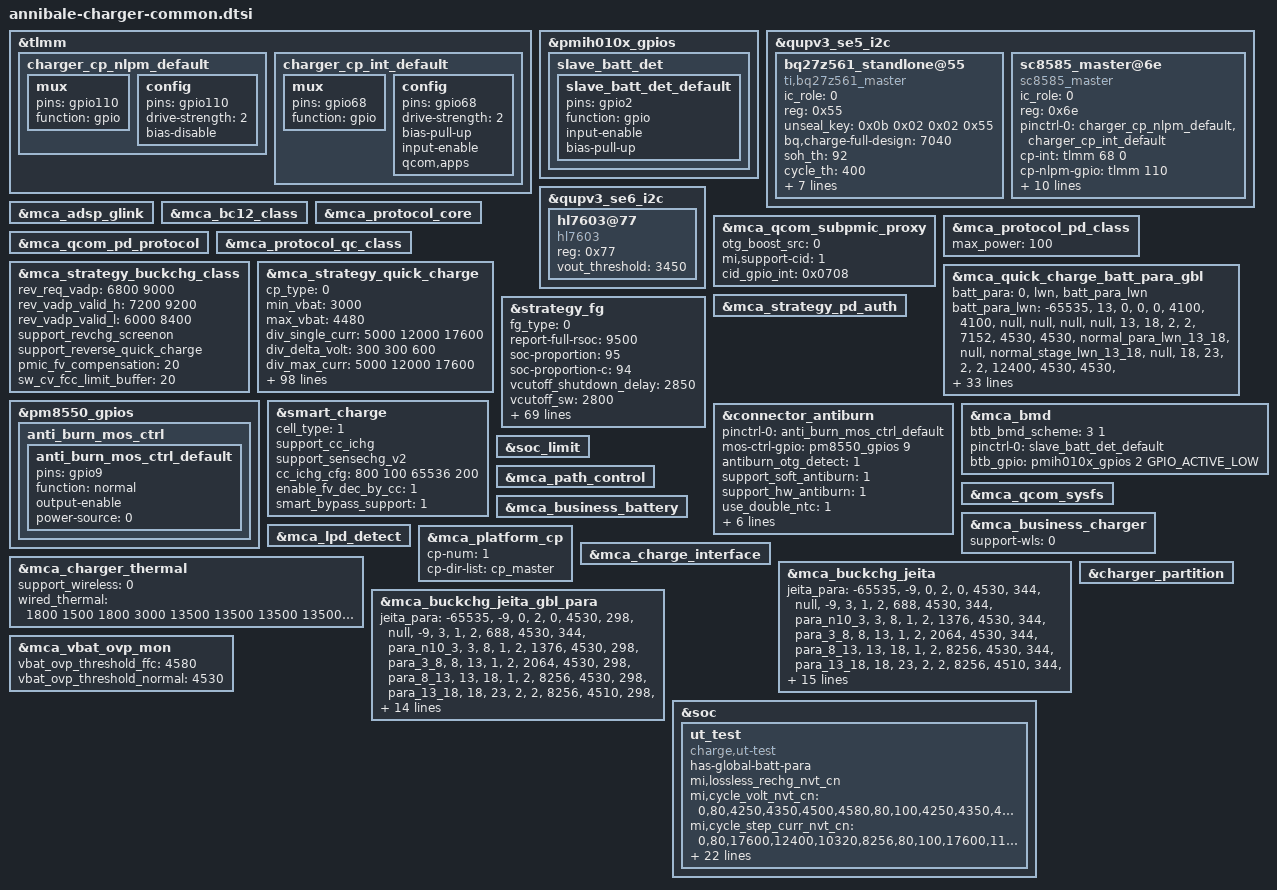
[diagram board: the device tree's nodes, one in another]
#include "mca.dtsi"

&tlmm {
	charger_cp_nlpm_default: charger_cp_nlpm_default {
		mux {
			pins = "gpio110";
			function = "gpio";
		};
		config {
			pins = "gpio110";
			drive-strength = <2>;   /* 2 mA */
			bias-disable;
		};
	};
	charger_cp_int_default: charger_cp_int_default {
		mux {
			pins = "gpio68";
			function = "gpio";
		};
		config {
			pins = "gpio68";
			drive-strength = <2>;   /* 2 mA */
			bias-pull-up;
			input-enable;
			qcom,apps;
		};
	};
};

&pmih010x_gpios {
	slave_batt_det {
		slave_batt_det_default: slave_batt_det_default {
			pins = "gpio2";
			function = "gpio";
			input-enable;
			bias-pull-up;
		};
	};
};


&qupv3_se5_i2c {
	status = "ok";
	#address-cells = <1>;
	#size-cells = <0>;
	bq27z561_standlone@55 {
		compatible = "ti,bq27z561_master";
		ic_role = <0>;
		reg = <0x55>;
		unseal_key = /bits/ 8 <0x0b 0x02 0x02 0x55>;
		bq,charge-full-design = <7040>;
		soh_th = <92>;
		cycle_th = <400>;
		cycle_step = <50>;
		resistance-id = <100000>;
		support-voltage-record-level;
		version_number = /bits/ 8 <0x43>;
		start_byte_address = /bits/ 8 <10>;
		byte_length = /bits/ 8 <6>;
		record_voltage = /bits/ 8 <0xb2 0x0c 0x66 0x0d 0x88 0x13>;
		status = "ok";
	};

	sc8585_master@6e {
		compatible = "sc8585_master";
		status = "ok";
		ic_role = <0>;
		reg = <0x6e>;
		pinctrl-names = "default";
		pinctrl-0 = <&charger_cp_nlpm_default>,<&charger_cp_int_default>;
		cp-int= <&tlmm 68 0>;
		cp-nlpm-gpio = <&tlmm 110 0x00>;
		bat-ovp-threshold = <4750>;
		bat-ovp-alarm-threshold = <4650>;
		bus-ovp-threshold = <21000 11000 6000>;
		usb-ovp-threshold = <21000 14000 6500>;
		bus-ocp-threshold = <5100 5850 5000>;
		wpc-ovp-threshold = <21000>;
		out-ovp-threshold = <5000>;
		pmid2-uvp-threshold = <100>;
		pmid2-ovp-threshold = <600>;
		support_reverse_quick_charge;
	};
};

&qupv3_se6_i2c {
	status = "ok";
	#address-cells = <1>;
	#size-cells = <0>;
	hl7603@77 {
		compatible = "hl7603";
		reg = <0x77>;
		vout_threshold = <3450>;
	};
};

&mca_adsp_glink {
	status = "ok";
};

&mca_bc12_class {
	status = "ok";
};

&mca_qcom_subpmic_proxy {
	status = "ok";
	otg_boost_src = <0>;
	mi,support-cid = <1>;
	cid_gpio_int = <0x0708>;
};

&mca_protocol_core {
	status = "ok";
};

&mca_protocol_pd_class {
	status = "ok";
	max_power = <100>;
};

&mca_qcom_pd_protocol {
	status = "ok";
};

&mca_protocol_qc_class {
	status = "ok";
};

&mca_strategy_buckchg_class {
	status = "ok";
	//pps&pd_verify, other
	rev_req_vadp = <6800 9000>;
	rev_vadp_valid_h = <7200 9200>;
	rev_vadp_valid_l = <6000 8400>;
	support_revchg_screenon;
	support_reverse_quick_charge;
	pmic_fv_compensation = <20>;
	sw_cv_fcc_limit_buffer = <20>;
};

&mca_strategy_quick_charge {
	status = "ok";
	cp_type = <0>;
	min_vbat = <3000>;
	max_vbat = <4480>;
	div_single_curr = <5000 12000 17600>;
	div_delta_volt = <300 300 600>;
	div_max_curr = <5000 12000 17600>;
	max_power = <100000>;
	qc_normal_charge_fv = <4510>;
	en_buck_parallel_chg = <1>;
	fv_hys_delta_mv = <6>;
	curr_terminate_ratio = <120>;
	curr_terminate_section = <2000>;/* from test testing nominative */
	buck_icl_fcc_curr = <1000 3000>;
	use_buck_fcc_threshold = <14000>;
	ibus_compensation = <660 300 200>;
	has-global-batt-para;
	support_cp_vfc = <1>;
	third_pps_switch_pmic = <1>;
	vstep_para =
		"1", "2000", "2",
		"2", "2000", "4",
		"4", "8000", "25",
		"4", "4000", "17",
		"4", "2000", "8",
		"4", "1200", "5",
		"4", "800", "2";

	vfc_iout_fsw_map =
		"6000", "720",
		"0", "480";

	batt_para =
		"0", "atl", "batt_para_atl",
		"0", "lwn", "batt_para_lwn";

	/* -------------------- batt_para_atl start -------------------- */
	/* temp_low, temp_high, low_temp_hys, high_temp_hys, max_current, volt_para_name stage_para_name */
	batt_para_atl =
		"-65535", "13", "0", "0", "0", "4100", "4100", "null", "null", "null", "null",
		"13", "18", "2", "2", "8256", "4530", "4530", "normal_para_atl_13_18", "null", "normal_stage_atl_13_18", "null",
		"18", "23", "2", "2", "12400", "4510", "4580", "normal_para_atl_18_23", "ffc_para_atl_18_23", "null", "ffc_stage_atl_18_23",
		"23", "35", "2", "2", "17600", "4510", "4580", "normal_para_atl_23_35", "ffc_para_atl_23_35", "normal_stage_atl_13_18", "ffc_stage_atl_23_35",
		"35", "40", "2", "2", "17600", "4500", "4580", "normal_para_atl_35_40", "ffc_para_atl_35_40", "normal_stage_atl_13_18", "ffc_stage_atl_23_35",
		"40", "48", "2", "2", "17600", "4490", "4580", "normal_para_atl_40_48", "ffc_para_atl_40_48", "normal_stage_atl_13_18", "ffc_stage_atl_23_35",
		"48", "65535", "0", "0", "0", "4100", "4100", "null", "null", "null", "null";

	normal_para_atl_13_18 =
		"4200", "8256", "6880",
		"4530", "6880", "344";
	normal_stage_atl_13_18 = <0 1 0 0>;

	normal_para_atl_18_23 =
		"4510", "8256", "344";

	ffc_para_atl_18_23 =
		"4250", "12400", "10320",
		"4500", "10320", "8256",
		"4573", "8256", "1582";
	ffc_stage_atl_18_23 = <0 0 0 0 0 0>;

	normal_para_atl_23_35 =
		"4250", "17600", "8256",
		"4510", "8256", "344";

	ffc_para_atl_23_35 =
		"4250", "17600", "12400",
		"4350", "12400", "10320",
		"4500", "10320", "8256",
		"4573", "8256", "1582";
	ffc_stage_atl_23_35 = <0 1 0 0 0 0 0 0>;

	normal_para_atl_35_40 =
		"4250", "17600", "8256",
		"4500", "8256", "344";

	ffc_para_atl_35_40 =
		"4250", "17600", "12400",
		"4350", "12400", "10320",
		"4500", "10320", "8256",
		"4573", "8256", "2339";

	normal_para_atl_40_48 =
		"4250", "17600", "8256",
		"4490", "8256", "344";

	ffc_para_atl_40_48 =
		"4250", "17600", "12400",
		"4350", "12400", "10320",
		"4500", "10320", "8256",
		"4573", "8256", "3234";
	/* -------------------- batt_para_atl end -------------------- */

	/* -------------------- batt_para_lwn start -------------------- */
	/* temp_low, temp_high, low_temp_hys, high_temp_hys, max_current, volt_para_name stage_para_name */
	batt_para_lwn =
		"-65535", "13", "0", "0", "0", "4100", "4100", "null", "null", "null", "null",
		"13", "18", "2", "2", "8256", "4530", "4530", "normal_para_lwn_13_18", "null", "normal_stage_lwn_13_18", "null",
		"18", "23", "2", "2", "12400", "4510", "4580", "normal_para_lwn_18_23", "ffc_para_lwn_18_23", "null", "ffc_stage_lwn_18_23",
		"23", "35", "2", "2", "17600", "4510", "4580", "normal_para_lwn_23_35", "ffc_para_lwn_23_35", "normal_stage_lwn_13_18", "ffc_stage_lwn_23_35",
		"35", "40", "2", "2", "17600", "4500", "4580", "normal_para_lwn_35_40", "ffc_para_lwn_35_40", "normal_stage_lwn_13_18", "ffc_stage_lwn_23_35",
		"40", "48", "2", "2", "17600", "4490", "4580", "normal_para_lwn_40_48", "ffc_para_lwn_40_48", "normal_stage_lwn_13_18", "ffc_stage_lwn_23_35",
		"48", "65535", "0", "0", "0", "4100", "4100", "null", "null", "null", "null";

	normal_para_lwn_13_18 =
		"4200", "8256", "6880",
		"4530", "6880", "344";
	normal_stage_lwn_13_18 = <0 1 0 0>;

	normal_para_lwn_18_23 =
		"4510", "8256", "344";

	ffc_para_lwn_18_23 =
		"4250", "12400", "10320",
		"4500", "10320", "8256",
		"4573", "8256", "1445";
	ffc_stage_lwn_18_23 = <0 0 0 0 0 0>;

	normal_para_lwn_23_35 =
		"4190", "17600", "8256",
		"4510", "8256", "344";

	ffc_para_lwn_23_35 =
		"4190", "17600", "12400",
		"4290", "12400", "10320",
		"4500", "10320", "8256",
		"4573", "8256", "2339";
	ffc_stage_lwn_23_35 = <0 1 0 0 0 0 0 0>;

	normal_para_lwn_35_40 =
		"4190", "17600", "8256",
		"4500", "8256", "344";

	ffc_para_lwn_35_40 =
		"4190", "17600", "12400",
		"4290", "12400", "10320",
		"4500", "10320", "8256",
		"4573", "8256", "2890";

	normal_para_lwn_40_48 =
		"4190", "17600", "8256",
		"4490", "8256", "344";

	ffc_para_lwn_40_48 =
		"4190", "17600", "12400",
		"4290", "12400", "10320",
		"4500", "10320", "8256",
		"4573", "8256", "3771";
	/* -------------------- batt_para_lwn end -------------------- */
};

&mca_quick_charge_batt_para_gbl {
	batt_para =
		"0", "lwn", "batt_para_lwn";
	/* temp_low, temp_high, low_temp_hys, high_temp_hys, max_current, normal_fv, ffc_fv,volt_para_name stage_para_name*/
	batt_para_lwn =
		"-65535", "13", "0", "0", "0", "4100", "4100", "null", "null", "null", "null",
		"13", "18", "2", "2", "7152", "4530", "4530", "normal_para_lwn_13_18", "null", "normal_stage_lwn_13_18", "null",
		"18", "23", "2", "2", "12400", "4530", "4530", "normal_para_lwn_18_23", "null", "normal_stage_lwn_13_18", "null",
		"23", "35", "2", "2", "17600", "4510", "4580", "normal_para_lwn_23_35", "ffc_para_lwn_23_35", "normal_stage_lwn_13_18", "ffc_stage_lwn_23_35",
		"35", "40", "2", "2", "17600", "4500", "4580", "normal_para_lwn_35_40", "ffc_para_lwn_35_40", "normal_stage_lwn_13_18", "ffc_stage_lwn_23_35",
		"40", "48", "2", "2", "17600", "4490", "4580", "normal_para_lwn_40_48", "ffc_para_lwn_40_48", "normal_stage_lwn_13_18", "ffc_stage_lwn_23_35",
		"48", "65535", "0", "0", "0", "4100", "4100", "null", "null", "null", "null";

	normal_para_lwn_13_18 =
		"4200", "7152", "5960",
		"4530", "5960", "298";
	normal_stage_lwn_13_18 = <0 1 0 0>;

	normal_para_lwn_18_23 =
		"4200", "11920", "8940",
		"4530", "8940", "298";

	normal_para_lwn_23_35 =
		"4080", "17600", "7152",
		"4510", "7152", "298";

	ffc_para_lwn_23_35 =
		"4080", "17600", "12400",
		"4180", "12400", "10728",
		"4400", "10728", "8940",
		"4500", "8940", "7152",
		"4580", "7152", "2622";
	ffc_stage_lwn_23_35 = <0 1 0 0 0 0 0 0 0 0>;

	normal_para_lwn_35_40 =
		"4080", "17600", "7152",
		"4500", "7152", "298";

	ffc_para_lwn_35_40 =
		"4080", "17600", "12400",
		"4180", "12400", "10728",
		"4400", "10728", "8940",
		"4500", "8940", "7152",
		"4580", "7152", "3456";

	normal_para_lwn_40_48 =
		"4080", "17600", "7152",
		"4490", "7152", "298";

	ffc_para_lwn_40_48 =
		"4080", "17600", "12400",
		"4180", "12400", "10728",
		"4400", "10728", "8940",
		"4500", "8940", "7152",
		"4580", "7152", "4768";
};

&mca_strategy_pd_auth {
	status = "ok";
};

&strategy_fg {
	status = "ok";
	fg_type = <0>;
	report-full-rsoc = <9500>;
	soc-proportion = <95>;
	soc-proportion-c = <94>;
	vcutoff_shutdown_delay = <2850>;
	vcutoff_sw = <2800>;
	vcutoff_fw = <2850>;
	support-cc-vcutoff;
	support-vpack-low-shutdown;
	cc_vcutoff_cfg =
		"-65535", "0", "0", "2", "cc_para0",
		"0", "65535", "2", "0", "cc_para1";
	cc_para0 =
		"600", "2650", "2600", "2500",
		"1200", "2900", "2850", "2800",
		"65535", "3150", "3100", "3050";
	cc_para1 =
		"200", "2850", "2850", "2800",
		"600", "3050", "3050", "3000",
		"1200", "3150", "3150", "3100",
		"65535", "3250", "3250", "3200";
	support-dod-vcutoff;
	weight = <28 20 14>;
	/*temp_low, temp_high, low_temp_hys, high_temp_hys, vterm, vterm_para_name*/
	dod_vcutoff_cfg =
		"-65535", "-6", "0", "2", "dod_para0",
		"-6", "0", "2", "2", "dod_para1",
		"0", "10", "2", "2", "dod_para2",
		"10", "60", "2", "0", "dod_para3",
		"60", "65535", "2", "0", "dod_para4";
	/*dod_count, vterm_fw, vterm_shutdown_delay, vempty*/
	dod_para0 =
		"58", "2650", "2600", "2500",
		"128", "2700", "2650", "2600",
		"278", "2750", "2700", "2650",
		"65535", "2850", "2800", "2750";
	dod_para1 =
		"58", "2700", "2650", "2600",
		"128", "2850", "2800", "2750",
		"278", "2950", "2900", "2850",
		"65535", "3000", "2950", "2900";
	dod_para2 =
		"58", "2750", "2750", "2700",
		"128", "2900", "2900", "2850",
		"278", "3000", "3000", "2950",
		"65535", "3100", "3100", "3050";
	dod_para3 =
		"58", "2850", "2850", "2800",
		"128", "3050", "3050", "3000",
		"278", "3150", "3150", "3100",
		"65535", "3250", "3250", "3200";
	dod_para4 =
		"65535", "3250", "3250", "3200";

	support-cc-vcutoff-global;
	/* temp_low, temp_high, low_temp_hys, high_temp_hys, vterm_para_name */
	cc_vcutoff_cfg_gl =
		"-65535", "0", "0", "2", "cc_para0_gl",
		"0", "65535", "2", "0", "cc_para1_gl";
	/* cycle_count, vterm_fw, vterm_shutdown_delay, vempty */
	cc_para0_gl =
		"600", "2900", "2850", "2800",
		"1200", "3150", "3100", "3050",
		"65535", "3250", "3200","3150";
	cc_para1_gl =
		"600", "3050", "3050", "3000",
		"1200", "3150", "3150","3100",
		"65535", "3250", "3250", "3200";

	support-dod-vcutoff-global;
	weight-global = <24 17 14>;
	/* temp_low, temp_high, low_temp_hys, high_temp_hys, vterm_para_name */
	dod_vcutoff_cfg_gl =
		"-65535", "-6", "0", "2", "dod_para0_gl",
		"-6", "0", "2", "2", "dod_para1_gl",
		"0", "10", "2", "2", "dod_para2_gl",
		"10", "60", "2", "0", "dod_para3_gl",
		"60", "65535", "2", "0", "dod_para4_gl";
	/* dod_count, vterm_fw, vterm_shutdown_delay, vempty */
	dod_para0_gl =
		"84", "2900", "2850", "2800",
		"213", "3000", "2950", "2900",
		"65535", "3050", "3000", "2950";
	dod_para1_gl =
		"84", "2900", "2850", "2800",
		"213", "3050", "3000", "2950",
		"65535", "3150", "3100", "3050";
	dod_para2_gl =
		"84", "2950", "2950", "2900",
		"213", "3050", "3050", "3000",
		"65535", "3150", "3150", "3100";
	dod_para3_gl =
		"84", "3050", "3050", "3000",
		"213", "3150", "3150", "3100",
		"65535", "3250", "3250", "3200";
	dod_para4_gl =
		"65535", "3250", "3250", "3200";

	adapt_power = <100>;
	show-model-by-country-version;
	model-name = "P11_7100mah_100w";
	model-name-global = "P11_6210mah_100w";
	support_full_design_gl;
	charge-full-design = <7100>;
	charge-full-design-gl = <6210>;
	support_dtpt = <1>;
	terminated_by_cp = <1>;
	clear_CC_per_hundred = <0>;
	fg_hightemp_vterm = <4200>;
	support-lossless-rechg = <1>;
	lossless_rechg_cfg = <15 47 300>;
	support_normal_force_full;
	fast_force_full_voltage_delta = <20>;
	extreme_cold_temp_compemsation =
		"100", "50", "70",
		"100", "150", "70",
		"350", "150", "80",
		"2147483647", "150", "100";
};

&pm8550_gpios {
        anti_burn_mos_ctrl {
                anti_burn_mos_ctrl_default: anti_burn_mos_ctrl_default {
                        pins = "gpio9";
                        function = "normal";
                        output-enable;
                        //drive-strength = <2>;
                        power-source = <0>;
                };
        };
};

&connector_antiburn {
	status = "ok";
	pinctrl-names = "default";
	pinctrl-0 = <&anti_burn_mos_ctrl_default>;
	mos-ctrl-gpio = <&pm8550_gpios 9 0>;
	antiburn_otg_detect = <1>;
	support_soft_antiburn = <1>;
	support_hw_antiburn = <1>;
	use_double_ntc = <1>;
	monitor_interval = <1000>;
	thermal-zone-name = "conn_therm";
	thermal-zone-name2 = "conn_therm2";
	max_temp_increase_rate = <4>; /*ntc temperature increase speed per second.*/
	otg_boost_src = <0>;
	en_src = <0>;      //OTG_EN_BOOST
	//thermal-board-temp-name = "board_sensor_therm";
};

&mca_bmd {
	status = "ok";
	btb_bmd_scheme = <3 1>;
	pinctrl-names = "default";
	pinctrl-0 = <&slave_batt_det_default>;
	btb_gpio = <&pmih010x_gpios 2 GPIO_ACTIVE_LOW>;
};

&smart_charge {
	status = "ok";
	cell_type = <1>;
	support_cc_ichg;
	support_sensechg_v2;
	cc_ichg_cfg = </* cyclecount delta_ichg*/
	800 100
	65536 200>;
	enable_fv_dec_by_cc = <1>;
	smart_bypass_support = <1>;
};

&soc_limit {
	status = "ok";
};

&mca_path_control {
	status = "ok";
};


&mca_qcom_sysfs {
	status = "ok";
};

&mca_business_battery {
	status = "ok";
};

&mca_business_charger {
	support-wls = <0>;
	status = "ok";
};

&mca_lpd_detect {
	status = "ok";
};

&mca_platform_cp {
	status = "ok";
	cp-num = <1>;
	cp-dir-list = "cp_master";
};

&mca_charge_interface
{
	status = "ok";
};

&mca_charger_thermal
{
	status = "ok";
	support_wireless = <0>;
	/* 5v_in 9v_in 5v_ichg 9v_ichg div1_single div1_multi div2_single div2_multi div4_single div4_multi*/
	wired_thermal = <
		1800 1500 1800 3000 13500 13500 13500 13500 13500 13500 /* level 1 */
		1800 1500 1800 3000 11000 11000 11000 11000 11000 11000 /* level 2 */
		1800 1500 1800 3000 9000  9000  9000  9000  9000  9000  /* level 3 */
		1800 1500 1800 3000 8000  8000  8000  8000  8000  8000  /* level 4 */
		1800 1500 1800 3000 7000  7000  7000  7000  7000  7000  /* level 5 */
		1800 1400 1800 2800 6000  6000  6000  6000  6000  6000  /* level 6 */
		1800 1300 1800 2600 5000  5000  5000  5000  5000  5000  /* level 7 */
		1800 1150 1800 2310 4000  4000  4000  4000  4000  4000  /* level 8 */
		1700 1100 1700 2200 3500  3500  3500  3500  3500  3500  /* level 9 */
		1600 1000 1600 2000 3000  3000  3000  3000  3000  3000  /* level 10 */
		1400 900  1400 1800 2500  2500  2500  2500  2500  2500  /* level 11 */
		1200 850  1200 1600 2000  2000  2000  2000  2000  2000  /* level 12 */
		1100 750  1100 1500 1500  1500  1500  1500  1500  1500  /* level 13 */
		1100 650  1000 1000 1000  1000  1000  1000  1000  1000  /* level 14 */
		1100 600  500  500  500   500   500   500   500   500   /* level 15 */
	>;
};

&mca_buckchg_jeita
{
	status = "ok";

	/* temp_low, temp_high, low_temp_hys, high_temp_hys, max_current, vterm, iterm volt_para_name */
	jeita_para =
		"-65535", "-9", "0", "2", "0", "4530", "344", "null",
		"-9", "3", "1", "2", "688", "4530", "344", "para_n10_3",
		"3", "8", "1", "2", "1376", "4530", "344", "para_3_8",
		"8", "13", "1", "2", "2064", "4530", "344", "para_8_13",
		"13", "18", "1", "2", "8256", "4530", "344", "para_13_18",
		"18", "23", "2", "2", "8256", "4510", "344", "null",
		"23", "35", "2", "2", "17600", "4510", "344", "null",
		"35", "40", "2", "2", "17600", "4500", "344", "null",
		"40", "48", "2", "2", "17600", "4490", "344", "null",
		"48", "55", "2", "2", "3440", "4100", "344", "null",
		"55", "65535", "2", "2", "0", "4100", "344", "null";
		para_n10_3 =
			"4200", "688",
			"4530", "550";
		para_3_8 =
 			"4200", "1376",
 			"4530", "1032";
		para_8_13 =
 			"4200", "2064",
 			"4530", "1376";
		para_13_18 =
 			"4200", "8256",
 			"4530", "6880";

	jeita_para_ffc =
		"18", "23", "2", "2", "12400", "4573", "1445", "null",
		"23", "35", "2", "2", "17600", "4573", "2339", "null",
		"35", "40", "2", "2", "17600", "4573", "2890", "null",
		"40", "48", "2", "2", "17600", "4573", "3371", "null",
		"48", "55", "2", "2", "3440", "4060", "344", "null",
		"55", "65535", "2", "2", "0", "4060", "344", "null";
};

&mca_buckchg_jeita_gbl_para {
	/* temp_low, temp_high, low_temp_hys, high_temp_hys, max_current, vterm, iterm volt_para_name */
	jeita_para =
		"-65535", "-9", "0", "2", "0", "4530", "298", "null",
		"-9", "3", "1", "2", "688", "4530", "344", "para_n10_3",
		"3", "8", "1", "2", "1376", "4530", "298", "para_3_8",
		"8", "13", "1", "2", "2064", "4530", "298", "para_8_13",
		"13", "18", "1", "2", "8256", "4530", "298", "para_13_18",
		"18", "23", "2", "2", "8256", "4510", "298", "null",
		"23", "35", "2", "2", "17600", "4510", "298", "null",
		"35", "40", "2", "2", "17600", "4500", "298", "null",
		"40", "48", "2", "2", "17600", "4490", "298", "null",
		"48", "55", "2", "2", "3440", "4100", "298", "null",
		"55", "65535", "2", "2", "0", "4100", "298", "null";

	para_n10_3 =
		"4200", "894",
		"4530", "596";
	para_3_8 =
		"4200", "1192",
		"4530", "894";
	para_8_13 =
		"4200", "1788",
		"4530", "1192";
	para_13_18 =
		"4200", "7152",
		"4530", "5960";

	jeita_para_ffc =
		"23", "35", "2", "2", "17600", "4580", "2622", "null",
		"35", "40", "2", "2", "17600", "4580", "3456", "null",
		"40", "48", "2", "2", "17600", "4580", "4768", "null",
		"48", "55", "2", "2", "2980", "4060", "298", "null",
		"55", "65535", "2", "2", "0", "4060", "298", "null";
};

&charger_partition
{
	status = "ok";
};

&mca_vbat_ovp_mon {
	vbat_ovp_threshold_ffc = <4580>;
	vbat_ovp_threshold_normal = <4530>;
	status = "ok";
};

&soc {
	ut_test {
		compatible = "charge,ut-test";
		status = "ok";
		has-global-batt-para;

		mi,lossless_rechg_nvt_cn;
		mi,cycle_volt_nvt_cn = "0,80,4250,4350,4500,4580,80,100,4250,4350,4480,4580,100,180,4200,4320,4460,4560,180,300,4200,4320,4440,4560,300,800,4200,4320,4420,4550,800,10000,4200,4320,4420,4530";
		mi,cycle_step_curr_nvt_cn = "0,80,17600,12400,10320,8256,80,100,17600,11780,9804,7843,100,180,17600,11160,9288,7430,180,300,17600,10540,8772,7018,300,10000,17600,9920,8256,6605";
		mi,temp_term_curr_nvt_cn = "23,35,1582,35,40,2339,40,48,3234";
		mi,thermal_nvt_cn = "13500,11000,9000,8000,7000,6000,5000,4000,3500,3000,2500,2000,1500,1000,500";

		mi,lossless_rechg_swd_cn;
		mi,cycle_volt_swd_cn = "0,80,4190,4290,4500,4580,80,100,4190,4290,4480,4580,100,180,4140,4260,4460,4560,180,300,4140,4260,4440,4560,300,800,4140,4260,4420,4550,800,10000,4140,4260,4420,4530";
		mi,cycle_step_curr_swd_cn= "0,80,17600,12400,10320,8256,80,100,17600,11780,9804,7843,100,180,17600,11160,9288,7430,180,300,17600,10540,8772,7018,300,10000,17600,9920,8256,6605";
		mi,temp_term_curr_swd_cn = "20,35,2339,35,40,2890,40,48,3371";
		mi,thermal_swd_cn = "13500,11000,9000,8000,7000,6000,5000,4000,3500,3000,2500,2000,1500,1000,500";

		mi,lossless_rechg_swd_global;
		mi,cycle_volt_swd_global = "0,100,4080,4180,4400,4500,4580,100,150,4050,4150,4400,4500,4560,150,300,4050,4150,4400,4500,4560,300,800,4050,4150,4400,4500,4550,800,10000,4050,4150,4400,4490,4530";
		mi,cycle_step_curr_swd_global = "0,800,17600,12400,10728,8940,7152,800,10000,14080,9920,8582,7152,5722";
		mi,temp_term_curr_swd_global = "20,35,2622,35,40,3456,40,48,4768";
		mi,thermal_swd_global = "13500,11000,9000,8000,7000,6000,5000,4000,3500,3000,2500,2000,1500,1000,500";
	};
};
